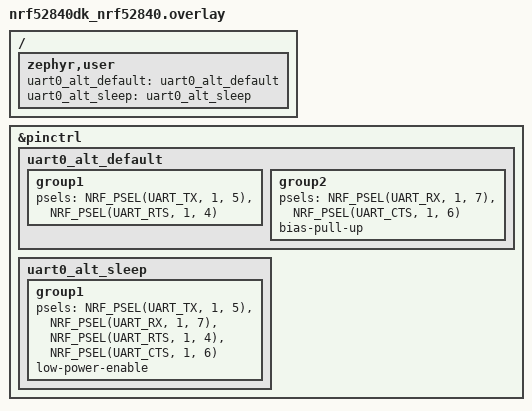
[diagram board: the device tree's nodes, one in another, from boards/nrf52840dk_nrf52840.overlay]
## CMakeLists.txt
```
# SPDX-License-Identifier: Apache-2.0

cmake_minimum_required(VERSION 3.28.0)

find_package(Zephyr REQUIRED HINTS $ENV{ZEPHYR_BASE})
project(dynamic_pinctrl)

target_sources(app PRIVATE src/main.c src/remap.c)
```

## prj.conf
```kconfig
CONFIG_PINCTRL=y
CONFIG_PINCTRL_DYNAMIC=y
# configure serial and console to come after remap hook
CONFIG_SERIAL_INIT_PRIORITY=60
CONFIG_CONSOLE_INIT_PRIORITY=70
CONFIG_GPIO=y
```

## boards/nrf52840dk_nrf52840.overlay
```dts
/*
 * Copyright (c) 2021 Nordic Semiconductor ASA
 * SPDX-License-Identifier: Apache-2.0
 */

/ {
	zephyr,user {
		uart0_alt_default = <&uart0_alt_default>;
		uart0_alt_sleep = <&uart0_alt_sleep>;
	};
};

&pinctrl {
	/* Alternative pin configuration for UART0 */
	uart0_alt_default: uart0_alt_default {
		group1 {
			psels = <NRF_PSEL(UART_TX, 1, 5)>,
				<NRF_PSEL(UART_RTS, 1, 4)>;
		};

		group2 {
			psels = <NRF_PSEL(UART_RX, 1, 7)>,
				<NRF_PSEL(UART_CTS, 1, 6)>;
			bias-pull-up;
		};
	};

	uart0_alt_sleep: uart0_alt_sleep {
		group1 {
			psels = <NRF_PSEL(UART_TX, 1, 5)>,
				<NRF_PSEL(UART_RX, 1, 7)>,
				<NRF_PSEL(UART_RTS, 1, 4)>,
				<NRF_PSEL(UART_CTS, 1, 6)>;
			low-power-enable;
		};
	};
};
```

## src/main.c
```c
/*
 * Copyright (c) 2021 Nordic Semiconductor ASA
 *
 * SPDX-License-Identifier: Apache-2.0
 */

#include <zephyr/sys/printk.h>

int main(void)
{
	printk("Hello World!\n");
	return 0;
}
```
